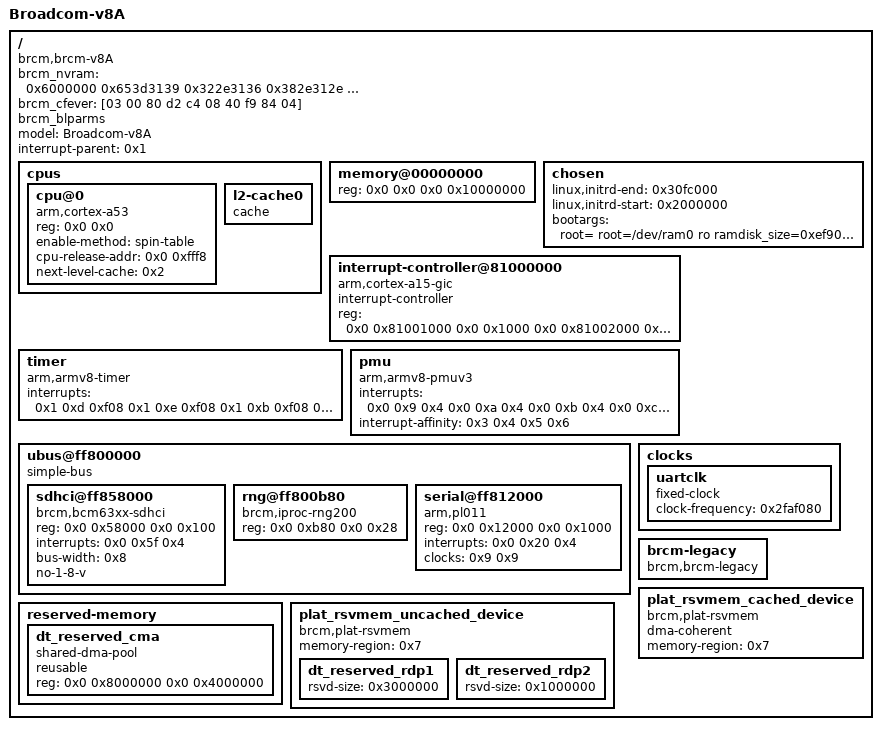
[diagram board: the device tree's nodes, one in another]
/dts-v1/;

/memreserve/	0x0000000000000000 0x0000000000020000;
/ {
	
	brcm_nvram = <0x6000000 0x653d3139 0x322e3136 0x382e312e 0x313a6666 0x66666666 0x30302068 0x3d313932 0x2e313638 0x2e312e31 0x30302067 0x3d20723d 0x6320663d 0x766d6c69 0x6e75785f 0x72645f62 0x6f6f7420 0x693d6263 0x6d393633 0x78785f66 0x735f6b65 0x726e656c 0x20643d31 0x20703d30 0x20633d72 0x616d6469 0x736b2061 0x3d307833 0x30303030 0x30302067 0x3d393633 0x3134362e 0x64746220 0x0 0x0 0x0 0x0 0x0 0x0 0x0 0x0 0x0 0x0 0x0 0x0 0x0 0x0 0x0 0x0 0x0 0x0 0x0 0x0 0x0 0x0 0x0 0x0 0x0 0x0 0x0 0x0 0x0 0x0 0x0 0x0 0x39363331 0x35385245 0x46334400 0xffffffff 0x0 0x80000000 0xa000000 0x101800 0xff00 0xffffffff 0xffffffff 0xffffffff 0xffffffff 0xffffffff 0xffffffff 0xffffffff 0xffffffff 0xffffffff 0xffffffff 0xffffffff 0xffffffff 0xffffffff 0xffffffff 0xffffffff 0xffffffff 0xffffffff 0xffffffff 0xffffffff 0xffffffff 0xffffffff 0xffffffff 0xffffffff 0xffffffff 0xffffffff 0xffffffff 0xffffffff 0xffffffff 0xffffffff 0xffffffff 0xffffffff 0xffffffff 0xffffffff 0xffffffff 0xffffffff 0xffffffff 0xffffffff 0xffffffff 0xffffffff 0xffffffff 0xffffffff 0xffffffff 0xffffffff 0xffffffff 0xffffffff 0xffffffff 0xffffffff 0xffffffff 0xffffffff 0xffffffff 0xffffffff 0xffffffff 0xffffffff 0xffffffff 0xffffffff 0xffffffff 0xffffffff 0xffffffff 0xffffffff 0xffffffff 0xffffffff 0xffffffff 0xffffffff 0xffffffff 0xffffffff 0xffffffff 0xffffffff 0xffffffff 0xffffffff 0xffffffff 0xffffffff 0xffffffff 0xffffff00 0x0 0x0 0x40000 0xc20700 0xd00f00 0xf00f00 0x40000 0xbe0700 0xbe0700 0x200000 0x100000 0x4e4f534c 0x49430000 0x0 0x0 0xffffffff 0xffffffff 0xffffffff 0xffffffff 0xffffffff 0xffffffff 0xffffffff 0xffffffff 0xffffffff 0xffffffff 0xffffffff 0xffffffff 0xffffffff 0xffffffff 0xffffffff 0xffffffff 0xffffffff 0xffffffff 0xff00ffff 0xffffffff 0x200c0000 0x2b150400 0x14000000 0x800 0xff 0xffffffff 0xffffffff 0xffffffff 0xffffffff 0xffffffff 0xffffffff 0xffffffff 0xffffffff 0xffffffff 0xffffffff 0xffffffff 0xffffffff 0xffffffff 0xffffffff 0xffffffff 0xffffffff 0xffffffff 0xffffffff 0xffffffff 0xffffffff 0xffffffff 0xffffffff 0xffffffff 0xffffffff 0xffffffff 0xffffffff 0xffffffff 0xffffffff 0xffffffff 0xffffffff 0xffffffff 0xffffffff 0xffffffff 0xffffffff 0xffffffff 0xffffffff 0xffffffff 0xffffffff 0xffffffff 0xffffffff 0xffffffff 0xffffffff 0xffffffff 0xffffffff 0xffffffff 0xffffffff 0xffffffff 0xffffffff 0xffffffff 0xffffffff 0xffffffff 0xffffffff 0xffffffff 0xffffffff 0xffffffff 0xffffffff 0xffffffff 0xffffffff 0xffffffff 0xffffffff 0xffffffff 0xffffffff 0xffffffff 0xffffffff 0xffffffff 0xffffffff 0xffffffff 0xffffffff 0x5009d689>;
	brcm_cfever = [03 00 80 d2 c4 08 40 f9 84 04];
	brcm_blparms;

	model = "Broadcom-v8A";
	compatible = "brcm,brcm-v8A";
	interrupt-parent = <0x1>;
	#address-cells = <0x2>;
	#size-cells = <0x2>;

	cpus {
		#address-cells = <0x2>;
		#size-cells = <0x0>;

		cpu@0 {
			device_type = "cpu";
			compatible = "arm,cortex-a53";
			reg = <0x0 0x0>;
			enable-method = "spin-table";
			cpu-release-addr = <0x0 0xfff8>;
			next-level-cache = <0x2>;
			phandle = <0x3>;
		};

		l2-cache0 {
			compatible = "cache";
			phandle = <0x2>;
		};
	};

	memory@00000000 {
		device_type = "memory";
		reg = <0x0 0x0 0x0 0x10000000>;
	};

        chosen {
                linux,initrd-end = <0x30fc000>;
                linux,initrd-start = <0x2000000>;
                bootargs = "root= root=/dev/ram0 ro  ramdisk_size=0xef9000  coherent_pool=4M cpuidle_sysfs_switch pci=pcie_bus_safe earlycon=pl011,0xff812000,1562500n8 lpj=800000 ikosboot console=ttyAMA0";
        };


	interrupt-controller@81000000 {
		compatible = "arm,cortex-a15-gic", "arm,cortex-a9-gic";
		#interrupt-cells = <0x3>;
		#address-cells = <0x0>;
		interrupt-controller;
		reg = <0x0 0x81001000 0x0 0x1000 0x0 0x81002000 0x0 0x2000>;
		phandle = <0x1>;
	};

	timer {
		compatible = "arm,armv8-timer";
		interrupts = <0x1 0xd 0xf08 0x1 0xe 0xf08 0x1 0xb 0xf08 0x1 0xa 0xf08>;
	};

	pmu {
		compatible = "arm,armv8-pmuv3";
		interrupts = <0x0 0x9 0x4 0x0 0xa 0x4 0x0 0xb 0x4 0x0 0xc 0x4>;
		interrupt-affinity = <0x3 0x4 0x5 0x6>;
	};

	ubus@ff800000 {
		compatible = "simple-bus";
		#address-cells = <0x2>;
		#size-cells = <0x2>;
		ranges = <0x0 0x0 0x0 0xff800000 0x0 0x62000>;

		sdhci@ff858000 {
			compatible = "brcm,bcm63xx-sdhci";
			reg = <0x0 0x58000 0x0 0x100>;
			interrupts = <0x0 0x5f 0x4>;
			bus-width = <0x8>;
			no-1-8-v;
		};

		rng@ff800b80 {
			compatible = "brcm,iproc-rng200";
			reg = <0x0 0xb80 0x0 0x28>;
		};
		serial@ff812000 {
                        compatible = "arm,pl011", "arm,primecell";
                        reg = <0x0 0x12000 0x0 0x1000>;
                        interrupts = <0x0 0x20 0x4>;
                        clocks = <0x9 0x9>;
                        clock-names = "uartclk", "apb_pclk";
                };

	};

	clocks {
                #address-cells = <0x2>;
                #size-cells = <0x2>;
                ranges;

	uartclk {
                        compatible = "fixed-clock";
                        #clock-cells = <0x0>;
                        clock-frequency = <0x2faf080>;
                        phandle = <0x9>;
                };
	};

	brcm-legacy {
		compatible = "brcm,brcm-legacy";
	};

	reserved-memory {
		#address-cells = <0x2>;
		#size-cells = <0x2>;
		ranges;

		dt_reserved_cma {
			compatible = "shared-dma-pool";
			reusable;
			//reg = <0x0 0x1c000000 0x0 0x4000000>;
			reg = <0x0 0x8000000 0x0 0x4000000>;
			phandle = <0x7>;
		};
	};

	plat_rsvmem_cached_device {
		compatible = "brcm,plat-rsvmem";
		dma-coherent;
		memory-region = <0x7>;
	};

	plat_rsvmem_uncached_device {
		compatible = "brcm,plat-rsvmem";
		memory-region = <0x7>;

		dt_reserved_rdp1 {
			rsvd-size = <0x3000000>;
		};

		dt_reserved_rdp2 {
			rsvd-size = <0x1000000>;
		};
	};
};
